AUTOSAR XML (schema 00054)
package /SwComponentTypes
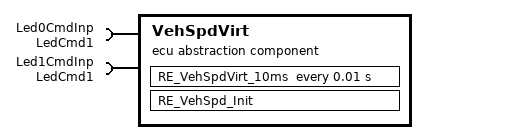
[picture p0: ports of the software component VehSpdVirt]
  ecu abstraction sw component type VehSpdVirt: hardware-element=IoDType
    require port Led0CmdInp: nonqueued-receiver-com-spec{data-element=Cmd, init-value=Default_Led0CmdInp:0}, required-interface=LedCmd1
    require port Led1CmdInp: nonqueued-receiver-com-spec{data-element=Cmd, init-value=Default_Led1CmdInp:0}, required-interface=LedCmd1
    behavior VehSpdVirt_IB: data-type-mapping=DataTypeMappingSet_LedOnOff
      timing event TE_10ms: start-on-event=RE_VehSpdVirt_10ms, period=0.01
      init event IE_WhlSpd_Init: start-on-event=RE_VehSpd_Init
      runnable RE_VehSpdVirt_10ms
        data-read-access:
          access DRA_Led0CmdInp: accessed-variable=Led0CmdInp.Cmd
          access DRA_Led1CmdInp: accessed-variable=Led1CmdInp.Cmd
      runnable RE_VehSpd_Init
